# nrf54h20_engb_radiocore register map
Vendor: Nordic Semiconductor; Series: nRF54h; File version: 1
CPU: CM33 r0p4, little endian, MPU, FPU, 3 interrupt priority bits, 480 interrupts, 8 SAU regions
Registers are 32-bit, read-write, reset 0x0 unless marked. A register's access mark holds for its fields unless they carry their own. Offsets are from the block's base; [hi:lo] are bit positions; lines under a group give offsets from that group; {n}, {i} and the like mark numbered series; 'fields as' and 'values as' point back to an identical list.

## AAR020_NS — Accelerated Address Resolver 0
Base 0x43026000
Same registers: AAR030_NS 0x4303A000, AAR031_NS 0x4303C000, AAR020_S 0x53026000, AAR030_S 0x5303A000, AAR031_S 0x5303C000
0x00 TASKS_START wo — Start resolving addresses based on IRKs specified in the IRK data structure
  [0] TASKS_START
    1=Trigger task
0x04 TASKS_STOP wo — Stop resolving addresses
  [0] TASKS_STOP
    1=Trigger task
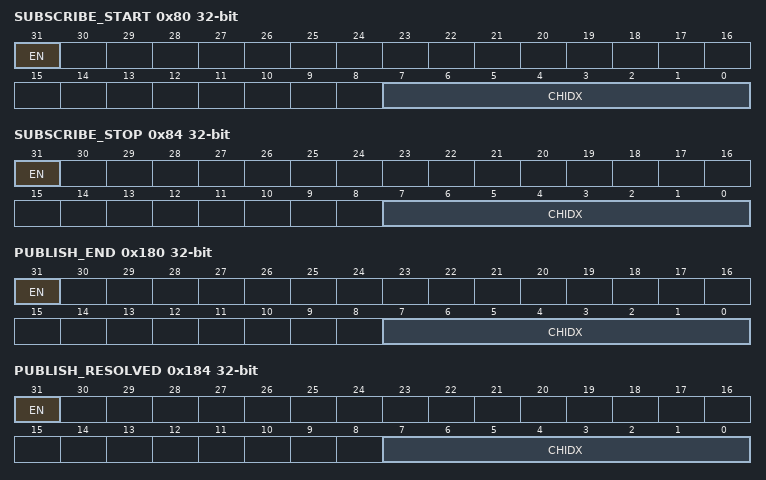
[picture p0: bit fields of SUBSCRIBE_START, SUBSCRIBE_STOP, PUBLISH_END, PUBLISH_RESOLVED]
0x80 SUBSCRIBE_START — Subscribe configuration for task START
  [31] EN
    0=Disabled (Disable subscription); 1=Enabled (Enable subscription)
  [7:0] CHIDX — DPPI channel that task START will subscribe to
0x84 SUBSCRIBE_STOP — Subscribe configuration for task STOP
  [31] EN
    values as SUBSCRIBE_START.EN
  [7:0] CHIDX — DPPI channel that task STOP will subscribe to
0x100 EVENTS_END — Address resolution procedure complete or ended due to an error
  [0] EVENTS_END
    0=NotGenerated (Event not generated); 1=Generated (Event generated)
0x104 EVENTS_RESOLVED — Address resolved
  [0] EVENTS_RESOLVED
    values as EVENTS_END.EVENTS_END
0x108 EVENTS_NOTRESOLVED — Address not resolved
  [0] EVENTS_NOTRESOLVED
    values as EVENTS_END.EVENTS_END
0x180 PUBLISH_END — Publish configuration for event END
  [31] EN
    0=Disabled (Disable publishing); 1=Enabled (Enable publishing)
  [7:0] CHIDX — DPPI channel that event END will publish to
0x184 PUBLISH_RESOLVED — Publish configuration for event RESOLVED
  [31] EN
    values as PUBLISH_END.EN
  [7:0] CHIDX — DPPI channel that event RESOLVED will publish to
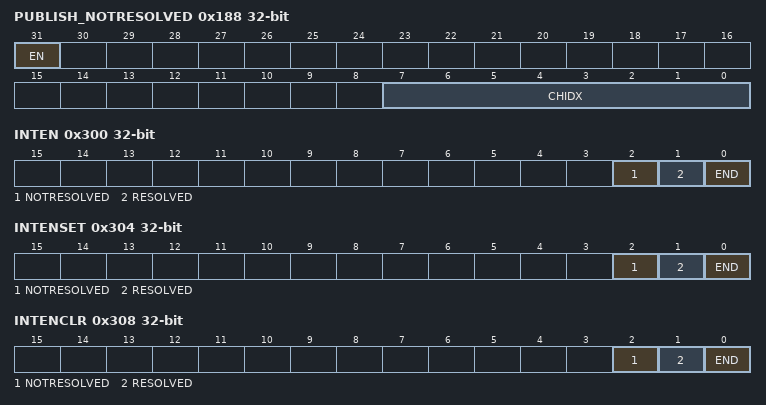
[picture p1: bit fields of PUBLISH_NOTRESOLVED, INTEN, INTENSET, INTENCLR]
0x188 PUBLISH_NOTRESOLVED — Publish configuration for event NOTRESOLVED
  [31] EN
    values as PUBLISH_END.EN
  [7:0] CHIDX — DPPI channel that event NOTRESOLVED will publish to
0x300 INTEN — Enable or disable interrupt
  [all] fields
    0=Disabled; 1=Enabled
  [2] NOTRESOLVED — Enable or disable interrupt for event NOTRESOLVED
  [1] RESOLVED — Enable or disable interrupt for event RESOLVED
  [0] END — Enable or disable interrupt for event END
0x304 INTENSET — Enable interrupt
  [all] fields
    on read: 0=Disabled (Read: Disabled); 1=Enabled (Read: Enabled) | on write: 1=Set (Enable)
  [2] NOTRESOLVED — Write '1' to enable interrupt for event NOTRESOLVED
  [1] RESOLVED — Write '1' to enable interrupt for event RESOLVED
  [0] END — Write '1' to enable interrupt for event END
0x308 INTENCLR — Disable interrupt
  [all] fields
    on read: 0=Disabled (Read: Disabled); 1=Enabled (Read: Enabled) | on write: 1=Clear (Disable)
  [2] NOTRESOLVED — Write '1' to disable interrupt for event NOTRESOLVED
  [1] RESOLVED — Write '1' to disable interrupt for event RESOLVED
  [0] END — Write '1' to disable interrupt for event END
0x500 ENABLE — Enable AAR
  [1:0] ENABLE — Enable or disable AAR
    0=Disabled; 3=Enabled
0x508 MAXRESOLVED reset 0x1 — Maximum number of IRKs to resolve
  [11:0] MAXRESOLVED — The maximum number of IRKs to resolve
0x530 IN group — IN EasyDMA channel
  0x00 PTR — Input pointer
    [31:0] PTR — Points to a job list containing AAR data structure
0x538 OUT group — OUT EasyDMA channel
  0x00 PTR — Output pointer
  0x04 AMOUNT ro — Number of bytes transferred in the last transaction
    [7:0] AMOUNT — Number of bytes written to memory after triggering the START task.

## ECB030_NS — AES ECB Mode Encryption 0
Base 0x4303B000
Same registers: ECB031_NS 0x4303D000, ECB030_S 0x5303B000, ECB031_S 0x5303D000
0x00 TASKS_START wo — Start ECB block encrypt
  [0] TASKS_START
    1=Trigger task
0x04 TASKS_STOP wo — Abort a possible executing ECB operation
  [0] TASKS_STOP
    1=Trigger task
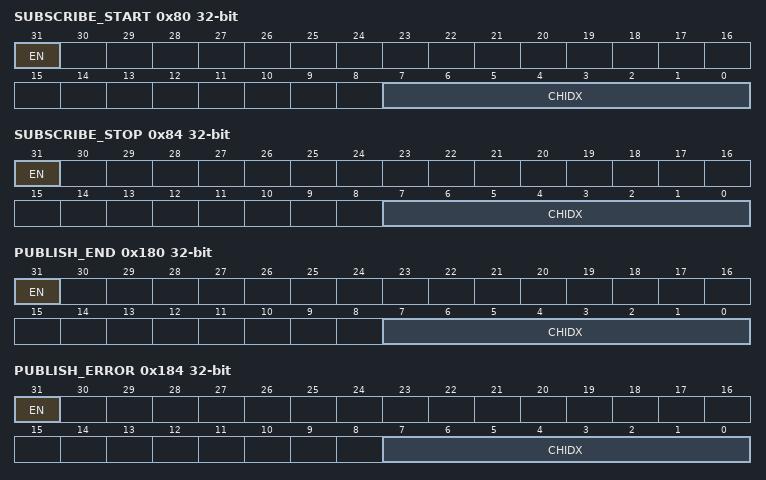
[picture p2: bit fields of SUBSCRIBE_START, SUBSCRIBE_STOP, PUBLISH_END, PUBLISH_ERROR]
0x80 SUBSCRIBE_START — Subscribe configuration for task START
  [31] EN
    0=Disabled (Disable subscription); 1=Enabled (Enable subscription)
  [7:0] CHIDX — DPPI channel that task START will subscribe to
0x84 SUBSCRIBE_STOP — Subscribe configuration for task STOP
  [31] EN
    values as SUBSCRIBE_START.EN
  [7:0] CHIDX — DPPI channel that task STOP will subscribe to
0x100 EVENTS_END — ECB block encrypt complete
  [0] EVENTS_END
    0=NotGenerated (Event not generated); 1=Generated (Event generated)
0x104 EVENTS_ERROR — ECB block encrypt aborted because of a STOP task or due to an error
  [0] EVENTS_ERROR
    values as EVENTS_END.EVENTS_END
0x180 PUBLISH_END — Publish configuration for event END
  [31] EN
    0=Disabled (Disable publishing); 1=Enabled (Enable publishing)
  [7:0] CHIDX — DPPI channel that event END will publish to
0x184 PUBLISH_ERROR — Publish configuration for event ERROR
  [31] EN
    values as PUBLISH_END.EN
  [7:0] CHIDX — DPPI channel that event ERROR will publish to
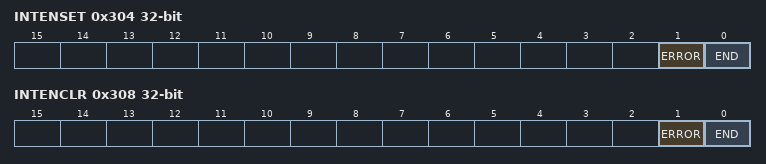
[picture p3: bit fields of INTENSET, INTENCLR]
0x304 INTENSET — Enable interrupt
  [1] ERROR — Write '1' to enable interrupt for event ERROR
    on read: 0=Disabled (Read: Disabled); 1=Enabled (Read: Enabled) | on write: 1=Set (Enable)
  [0] END — Write '1' to enable interrupt for event END
    values as ERROR
0x308 INTENCLR — Disable interrupt
  [1] ERROR — Write '1' to disable interrupt for event ERROR
    on read: 0=Disabled (Read: Disabled); 1=Enabled (Read: Enabled) | on write: 1=Clear (Disable)
  [0] END — Write '1' to disable interrupt for event END
    values as ERROR
0x510 KEY group — Unspecified
  {0x0+4j} VALUE[{j}] (j=0..3) wo — Description collection: 128-bit AES key
    [31:0] VALUE — AES 128-bit key value, bits (32*(n+1))-1 : (32*n)
0x530 IN group — IN EasyDMA channel
  0x00 PTR — Input pointer
    [31:0] PTR — Points to a job list containing unencrypted ECB data structure
0x538 OUT group — OUT EasyDMA channel
  0x00 PTR — Output pointer Points to a job list containing encrypted ECB data structure
    [31:0] PTR — Output pointer
0x53C CSAA group — Channel sounding access address scoring algorithm
  0x00 INITIATOR ro — Selected initiator for Channel Sounding Access Address
    [31:0] PN
  0x04 REFLECTOR ro — Selected initiator for Channel Sounding Access Address
    [31:0] PN
  0x08 MODE — Operation modes
    [0] BITREVERSE — Reverse the endianness on bit level for the ECB output, INITIATOR, and REFLECTOR registers
      0=Default endianness; 1=Reversed endianness
